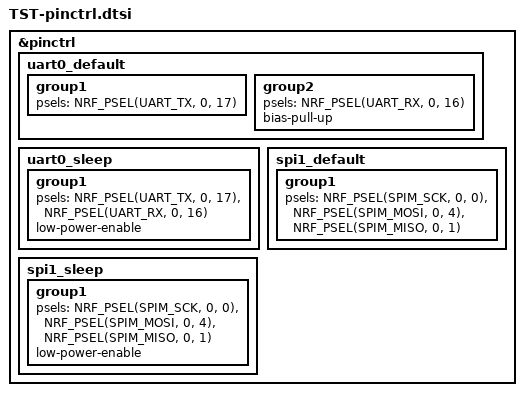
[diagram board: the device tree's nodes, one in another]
&pinctrl{

    uart0_default: uart0_default
     {
            group1 {
            psels = <NRF_PSEL(UART_TX, 0, 17)>;
            };

            group2 {
            psels = <NRF_PSEL(UART_RX, 0, 16)>;
            bias-pull-up;
            };

            };  
            
            uart0_sleep: uart0_sleep {
            group1 {
            psels = <NRF_PSEL(UART_TX, 0, 17)>,
            <NRF_PSEL(UART_RX, 0, 16)>;
            low-power-enable;
            };
         };

    	spi1_default: spi1_default {

            group1 {
            psels = <NRF_PSEL(SPIM_SCK, 0, 0)>,
            <NRF_PSEL(SPIM_MOSI, 0, 4)>,
            <NRF_PSEL(SPIM_MISO, 0, 1)>;
                };
            };  
            
            spi1_sleep: spi1_sleep {
            group1 {
            psels = <NRF_PSEL(SPIM_SCK, 0, 0)>,
            <NRF_PSEL(SPIM_MOSI, 0, 4)>,
            <NRF_PSEL(SPIM_MISO, 0, 1)>;
            low-power-enable;
            };
        };
};


